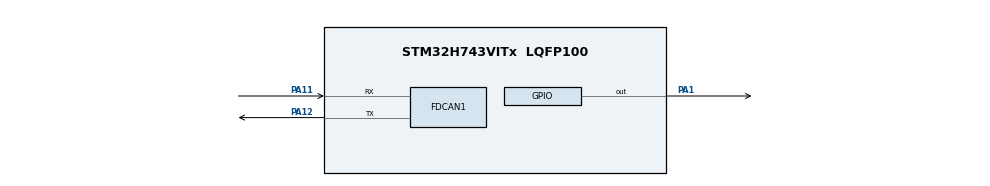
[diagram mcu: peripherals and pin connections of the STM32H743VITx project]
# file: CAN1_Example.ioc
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FDCAN1.DataPrescaler=8
FDCAN1.DataTimeSeg1=10
FDCAN1.DataTimeSeg2=9
FDCAN1.NominalPrescaler=8
FDCAN1.NominalTimeSeg1=10
FDCAN1.NominalTimeSeg2=9
FDCAN1.RxFifo0ElmtsNbr=1
FDCAN1.StdFiltersNbr=1
FDCAN1.TxFifoQueueElmtsNbr=1
Mcu.Family=STM32H7
Mcu.Name=STM32H743VITx
Mcu.Package=LQFP100
NVIC.FDCAN1_IT0_IRQn=true\:0\:0\:false\:false\:true\:true\:true
NVIC.PriorityGroup=NVIC_PRIORITYGROUP_4
PA1.Signal=GPIO_Output
PA11.Mode=FDCAN_Activate
PA11.Signal=FDCAN1_RX
PA12.Mode=FDCAN_Activate
PA12.Signal=FDCAN1_TX
PH0-OSC_IN\ (PH0).Mode=HSE-External-Oscillator
PH0-OSC_IN\ (PH0).Signal=RCC_OSC_IN
PH1-OSC_OUT\ (PH1).Mode=HSE-External-Oscillator
PH1-OSC_OUT\ (PH1).Signal=RCC_OSC_OUT
ProjectManager.HeapSize=0x200
ProjectManager.StackSize=0x400
ProjectManager.TargetToolchain=MDK-ARM V5.27
RCC.ADCFreq_Value=50390625
RCC.APB1Freq_Value=120000000
RCC.APB2Freq_Value=120000000
RCC.APB3Freq_Value=120000000
RCC.APB4Freq_Value=120000000
RCC.CortexFreq_Value=480000000
RCC.D1PPRE=RCC_APB3_DIV2
RCC.D2PPRE1=RCC_APB1_DIV2
RCC.D2PPRE2=RCC_APB2_DIV2
RCC.D3PPRE=RCC_APB4_DIV2
RCC.DIVM1=5
RCC.DIVN1=192
RCC.DIVQ1=12
RCC.HCLKFreq_Value=240000000
RCC.HPRE=RCC_HCLK_DIV2
RCC.PLLSourceVirtual=RCC_PLLSOURCE_HSE
RCC.SYSCLKFreq_VALUE=480000000
RCC.SYSCLKSource=RCC_SYSCLKSOURCE_PLLCLK
RCC.USBFreq_Value=80000000
board=custom

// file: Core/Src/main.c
/* USER CODE BEGIN Header */
/**
  ******************************************************************************
  * @file           : main.c
  * @brief          : Main program body
  ******************************************************************************
  * @attention
  *
  * <h2><center>&copy; Copyright (c) 2021 STMicroelectronics.
  * All rights reserved.</center></h2>
  *
  * This software component is licensed by ST under BSD 3-Clause license,
  * the "License"; You may not use this file except in compliance with the
  * License. You may obtain a copy of the License at:
  *                        opensource.org/licenses/BSD-3-Clause
  *
  ******************************************************************************
  */
/* USER CODE END Header */
#include "main.h"
#include "fdcan.h"
#include "gpio.h"

/* USER CODE BEGIN PV */
int8_t can_status=0;
int8_t can_fault =0;

FDCAN_TxHeaderTypeDef TxHeader;
FDCAN_RxHeaderTypeDef RxHeader;
uint8_t TxData[8] = {0};
uint8_t RxData[8];
void FDCAN1_Config(void);

/* USER CODE END PV */

void SystemClock_Config(void);

int main(void)
{

  /* MCU Configuration--------------------------------------------------------*/

  /* Reset of all peripherals, Initializes the Flash interface and the Systick. */
  HAL_Init();

  /* Configure the system clock */
  SystemClock_Config();

  /* Initialize all configured peripherals */
  MX_GPIO_Init();
  MX_FDCAN1_Init();
  /* USER CODE BEGIN 2 */
	FDCAN1_Config();
  /* USER CODE END 2 */

  /* Infinite loop */
  while (1)
  {

    /* USER CODE BEGIN 3 */
		TxHeader.Identifier = 0xC1;
    TxHeader.IdType = FDCAN_STANDARD_ID;
		TxHeader.TxFrameType = FDCAN_DATA_FRAME;
		TxHeader.DataLength = FDCAN_DLC_BYTES_8;
		TxHeader.ErrorStateIndicator = FDCAN_ESI_ACTIVE;
		TxHeader.BitRateSwitch = FDCAN_BRS_OFF;
		TxHeader.FDFormat = FDCAN_CLASSIC_CAN;
		TxHeader.TxEventFifoControl = FDCAN_NO_TX_EVENTS;
		TxHeader.MessageMarker = 0;
		//++TxData[7];
		if(HAL_FDCAN_AddMessageToTxFifoQ(&hfdcan1, &TxHeader, TxData) != HAL_OK) {
				can_fault=3;
				Error_Handler();

		}
		HAL_Delay(100);
		HAL_GPIO_TogglePin(GPIOA, GPIO_PIN_1);
		can_status=2;
  }
  /* USER CODE END 3 */
}

void SystemClock_Config(void)
{
  RCC_OscInitTypeDef RCC_OscInitStruct = {0};
  RCC_ClkInitTypeDef RCC_ClkInitStruct = {0};

  /** Supply configuration update enable
  */
  HAL_PWREx_ConfigSupply(PWR_LDO_SUPPLY);
  /** Configure the main internal regulator output voltage
  */
  __HAL_PWR_VOLTAGESCALING_CONFIG(PWR_REGULATOR_VOLTAGE_SCALE0);

  while(!__HAL_PWR_GET_FLAG(PWR_FLAG_VOSRDY)) {}
  /** Initializes the RCC Oscillators according to the specified parameters
  * in the RCC_OscInitTypeDef structure.
  */
  RCC_OscInitStruct.OscillatorType = RCC_OSCILLATORTYPE_HSE;
  RCC_OscInitStruct.HSEState = RCC_HSE_ON;
  RCC_OscInitStruct.PLL.PLLState = RCC_PLL_ON;
  RCC_OscInitStruct.PLL.PLLSource = RCC_PLLSOURCE_HSE;
  RCC_OscInitStruct.PLL.PLLM = 5;
  RCC_OscInitStruct.PLL.PLLN = 192;
  RCC_OscInitStruct.PLL.PLLP = 2;
  RCC_OscInitStruct.PLL.PLLQ = 12;
  RCC_OscInitStruct.PLL.PLLR = 2;
  RCC_OscInitStruct.PLL.PLLRGE = RCC_PLL1VCIRANGE_2;
  RCC_OscInitStruct.PLL.PLLVCOSEL = RCC_PLL1VCOWIDE;
  RCC_OscInitStruct.PLL.PLLFRACN = 0;
  if (HAL_RCC_OscConfig(&RCC_OscInitStruct) != HAL_OK)
  {
    Error_Handler();
  }
  /** Initializes the CPU, AHB and APB buses clocks
  */
  RCC_ClkInitStruct.ClockType = RCC_CLOCKTYPE_HCLK|RCC_CLOCKTYPE_SYSCLK
                              |RCC_CLOCKTYPE_PCLK1|RCC_CLOCKTYPE_PCLK2
                              |RCC_CLOCKTYPE_D3PCLK1|RCC_CLOCKTYPE_D1PCLK1;
  RCC_ClkInitStruct.SYSCLKSource = RCC_SYSCLKSOURCE_PLLCLK;
  RCC_ClkInitStruct.SYSCLKDivider = RCC_SYSCLK_DIV1;
  RCC_ClkInitStruct.AHBCLKDivider = RCC_HCLK_DIV2;
  RCC_ClkInitStruct.APB3CLKDivider = RCC_APB3_DIV2;
  RCC_ClkInitStruct.APB1CLKDivider = RCC_APB1_DIV2;
  RCC_ClkInitStruct.APB2CLKDivider = RCC_APB2_DIV2;
  RCC_ClkInitStruct.APB4CLKDivider = RCC_APB4_DIV2;

  if (HAL_RCC_ClockConfig(&RCC_ClkInitStruct, FLASH_LATENCY_4) != HAL_OK)
  {
    Error_Handler();
  }
}

/* USER CODE BEGIN 4 */
void FDCAN1_Config(void)
      {
      	FDCAN_FilterTypeDef sFilterConfig;
       /* Configure Rx filter */
        sFilterConfig.IdType = FDCAN_STANDARD_ID;
        sFilterConfig.FilterIndex = 0;
        sFilterConfig.FilterType = FDCAN_FILTER_RANGE;
        sFilterConfig.FilterConfig = FDCAN_FILTER_TO_RXFIFO0;
        sFilterConfig.FilterID1 = 0x04;
        sFilterConfig.FilterID2 = 0x06;
       if (HAL_FDCAN_ConfigFilter(&hfdcan1, &sFilterConfig) != HAL_OK)
        {
       Error_Handler();
        }
       /* Configure global filter:
       Filter all remote frames with STD and EXT ID
       Reject non matching frames with STD ID and EXT ID */
       if (HAL_FDCAN_ConfigGlobalFilter(&hfdcan1, FDCAN_REJECT, FDCAN_REJECT, FDCAN_FILTER_REMOTE, FDCAN_FILTER_REMOTE) != HAL_OK)
        {
       Error_Handler();
        }
       /* Start the FDCAN module */
       if (HAL_FDCAN_Start(&hfdcan1) != HAL_OK)
        {
					can_fault=1;
       Error_Handler();
        }
       if (HAL_FDCAN_ActivateNotification(&hfdcan1, FDCAN_IT_RX_FIFO0_NEW_MESSAGE, 0) != HAL_OK)
        {
					can_fault=2;
       Error_Handler();
        }
				can_status=1;
      }

      void HAL_FDCAN_RxFifo0Callback(FDCAN_HandleTypeDef *hfdcan, uint32_t RxFifo0ITs)
      {
       if((RxFifo0ITs & FDCAN_IT_RX_FIFO0_NEW_MESSAGE) != RESET)
        {
					can_fault=4;
					Error_Handler();
        }
      }
/* USER CODE END 4 */

void Error_Handler(void)
{
  /* USER CODE BEGIN Error_Handler_Debug */
  /* User can add his own implementation to report the HAL error return state */
  __disable_irq();
  while (1)
  {
		HAL_GPIO_WritePin(GPIOA,GPIO_PIN_1,GPIO_PIN_SET);
  }
  /* USER CODE END Error_Handler_Debug */
}

/************************ (C) COPYRIGHT STMicroelectronics *****END OF FILE****/
